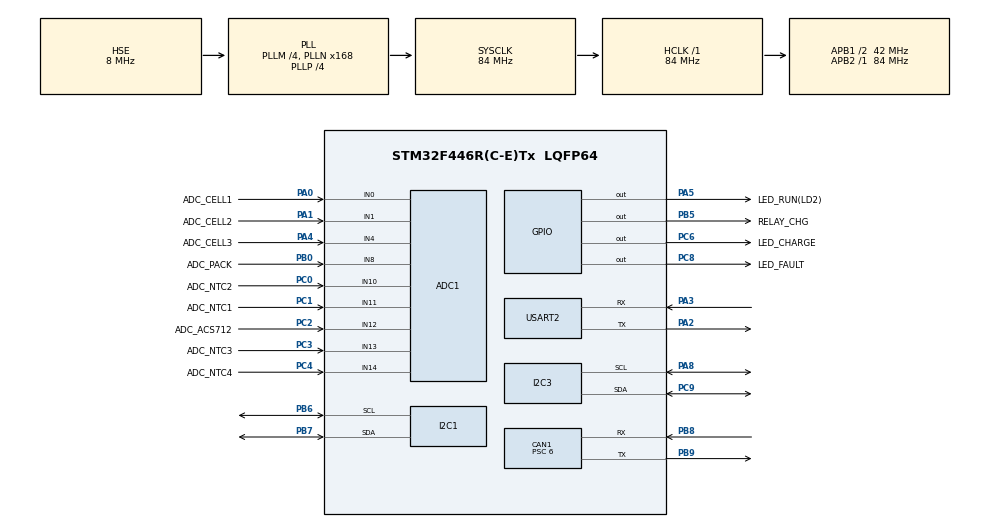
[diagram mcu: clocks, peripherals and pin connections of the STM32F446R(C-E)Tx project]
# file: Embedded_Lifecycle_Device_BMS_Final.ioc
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ADC1.Channel-0\#ChannelRegularConversion=ADC_CHANNEL_0
ADC1.Channel-1\#ChannelRegularConversion=ADC_CHANNEL_1
ADC1.Channel-2\#ChannelRegularConversion=ADC_CHANNEL_4
ADC1.Channel-3\#ChannelRegularConversion=ADC_CHANNEL_8
ADC1.Channel-4\#ChannelRegularConversion=ADC_CHANNEL_11
ADC1.Channel-5\#ChannelRegularConversion=ADC_CHANNEL_10
ADC1.Channel-6\#ChannelRegularConversion=ADC_CHANNEL_13
ADC1.Channel-7\#ChannelRegularConversion=ADC_CHANNEL_14
ADC1.Channel-8\#ChannelRegularConversion=ADC_CHANNEL_12
ADC1.Channel-9\#ChannelRegularConversion=ADC_CHANNEL_VREFINT
ADC1.ClockPrescaler=ADC_CLOCK_SYNC_PCLK_DIV8
ADC1.ContinuousConvMode=ENABLE
ADC1.DMAContinuousRequests=ENABLE
ADC1.NbrOfConversion=10
ADC1.NbrOfConversionFlag=1
ADC1.Rank-0\#ChannelRegularConversion=1
ADC1.Rank-1\#ChannelRegularConversion=2
ADC1.Rank-2\#ChannelRegularConversion=3
ADC1.Rank-3\#ChannelRegularConversion=4
ADC1.Rank-4\#ChannelRegularConversion=5
ADC1.Rank-5\#ChannelRegularConversion=6
ADC1.Rank-6\#ChannelRegularConversion=7
ADC1.Rank-7\#ChannelRegularConversion=8
ADC1.Rank-8\#ChannelRegularConversion=9
ADC1.Rank-9\#ChannelRegularConversion=10
ADC1.SamplingTime-0\#ChannelRegularConversion=ADC_SAMPLETIME_480CYCLES
ADC1.SamplingTime-1\#ChannelRegularConversion=ADC_SAMPLETIME_480CYCLES
ADC1.SamplingTime-2\#ChannelRegularConversion=ADC_SAMPLETIME_480CYCLES
ADC1.SamplingTime-3\#ChannelRegularConversion=ADC_SAMPLETIME_480CYCLES
ADC1.SamplingTime-4\#ChannelRegularConversion=ADC_SAMPLETIME_480CYCLES
ADC1.SamplingTime-5\#ChannelRegularConversion=ADC_SAMPLETIME_480CYCLES
ADC1.SamplingTime-6\#ChannelRegularConversion=ADC_SAMPLETIME_480CYCLES
ADC1.SamplingTime-7\#ChannelRegularConversion=ADC_SAMPLETIME_480CYCLES
ADC1.SamplingTime-8\#ChannelRegularConversion=ADC_SAMPLETIME_480CYCLES
ADC1.SamplingTime-9\#ChannelRegularConversion=ADC_SAMPLETIME_480CYCLES
ADC1.ScanConvMode=ENABLE
ADC1.master=1
CAN1.ABOM=ENABLE
CAN1.BS1=CAN_BS1_11TQ
CAN1.BS2=CAN_BS2_2TQ
CAN1.CalculateBaudRate=500000
CAN1.CalculateTimeBit=2000
CAN1.CalculateTimeQuantum=142.85714285714286
CAN1.Mode=CAN_MODE_NORMAL
CAN1.NART=ENABLE
CAN1.Prescaler=6
Dma.ADC1.0.Direction=DMA_PERIPH_TO_MEMORY
Dma.ADC1.0.FIFOMode=DMA_FIFOMODE_DISABLE
Dma.ADC1.0.Instance=DMA2_Stream0
Dma.ADC1.0.MemDataAlignment=DMA_MDATAALIGN_HALFWORD
Dma.ADC1.0.MemInc=DMA_MINC_ENABLE
Dma.ADC1.0.Mode=DMA_CIRCULAR
Dma.ADC1.0.PeriphDataAlignment=DMA_PDATAALIGN_HALFWORD
Dma.ADC1.0.PeriphInc=DMA_PINC_DISABLE
Dma.ADC1.0.Priority=DMA_PRIORITY_LOW
Dma.Request0=ADC1
I2C1.I2C_Mode=I2C_Fast
I2C3.I2C_Mode=I2C_Fast
Mcu.Family=STM32F4
Mcu.Name=STM32F446R(C-E)Tx
Mcu.Package=LQFP64
NVIC.CAN1_RX0_IRQn=true\:0\:0\:false\:false\:true\:true\:true\:true
NVIC.DMA2_Stream0_IRQn=true\:0\:0\:false\:false\:true\:false\:true\:true
NVIC.PriorityGroup=NVIC_PRIORITYGROUP_4
NVIC.USART2_IRQn=true\:0\:0\:false\:false\:true\:true\:true\:true
PA0-WKUP.GPIO_Label=ADC_CELL1
PA0-WKUP.Signal=ADCx_IN0
PA1.GPIO_Label=ADC_CELL2
PA1.Signal=ADCx_IN1
PA2.Mode=Asynchronous
PA2.Signal=USART2_TX
PA3.Mode=Asynchronous
PA3.Signal=USART2_RX
PA4.GPIO_Label=ADC_CELL3
PA4.Signal=ADCx_IN4
PA5.GPIO_Label=LED_RUN(LD2)
PA5.Signal=GPIO_Output
PA8.Mode=I2C
PA8.Signal=I2C3_SCL
PB0.GPIO_Label=ADC_PACK
PB0.Signal=ADCx_IN8
PB5.GPIO_Label=RELAY_CHG
PB5.Signal=GPIO_Output
PB6.Mode=I2C
PB6.Signal=I2C1_SCL
PB7.Mode=I2C
PB7.Signal=I2C1_SDA
PB8.Mode=CAN_Activate
PB8.Signal=CAN1_RX
PB9.Mode=CAN_Activate
PB9.Signal=CAN1_TX
PC0.GPIO_Label=ADC_NTC2
PC0.Signal=ADCx_IN10
PC1.GPIO_Label=ADC_NTC1
PC1.Signal=ADCx_IN11
PC2.GPIO_Label=ADC_ACS712
PC2.Signal=ADCx_IN12
PC3.GPIO_Label=ADC_NTC3
PC3.Signal=ADCx_IN13
PC4.GPIO_Label=ADC_NTC4
PC4.Signal=ADCx_IN14
PC6.GPIO_Label=LED_CHARGE
PC6.Signal=GPIO_Output
PC8.GPIO_Label=LED_FAULT
PC8.Signal=GPIO_Output
PC9.Mode=I2C
PC9.Signal=I2C3_SDA
PH0-OSC_IN.Mode=HSE-External-Clock-Source
PH0-OSC_IN.Signal=RCC_OSC_IN
PH1-OSC_OUT.Mode=HSE-External-Clock-Source
PH1-OSC_OUT.Signal=RCC_OSC_OUT
ProjectManager.HeapSize=0x200
ProjectManager.StackSize=0x400
ProjectManager.TargetToolchain=CMake
RCC.AHBFreq_Value=84000000
RCC.APB1CLKDivider=RCC_HCLK_DIV2
RCC.APB1Freq_Value=42000000
RCC.APB1TimFreq_Value=84000000
RCC.APB2Freq_Value=84000000
RCC.APB2TimFreq_Value=84000000
RCC.CortexFreq_Value=84000000
RCC.HCLKFreq_Value=84000000
RCC.HSE_VALUE=8000000
RCC.PLLM=4
RCC.PLLN=168
RCC.PLLP=RCC_PLLP_DIV4
RCC.PLLSourceVirtual=RCC_PLLSOURCE_HSE
RCC.SYSCLKFreq_VALUE=84000000
RCC.SYSCLKSource=RCC_SYSCLKSOURCE_PLLCLK
RCC.USBFreq_Value=168000000
RCC.VCOOutputFreq_Value=336000000
SH.ADCx_IN0.0=ADC1_IN0,IN0
SH.ADCx_IN1.0=ADC1_IN1,IN1
SH.ADCx_IN10.0=ADC1_IN10,IN10
SH.ADCx_IN11.0=ADC1_IN11,IN11
SH.ADCx_IN12.0=ADC1_IN12,IN12
SH.ADCx_IN13.0=ADC1_IN13,IN13
SH.ADCx_IN14.0=ADC1_IN14,IN14
SH.ADCx_IN4.0=ADC1_IN4,IN4
SH.ADCx_IN8.0=ADC1_IN8,IN8
USART2.VirtualMode=VM_ASYNC
VP_ADC1_Vref_Input.Mode=IN-Vrefint
board=custom

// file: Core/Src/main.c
/* USER CODE BEGIN Header */
/**
  ******************************************************************************
  * @file           : main.c
  * @brief          : Main program body
  ******************************************************************************
  * @attention
  *
  * Copyright (c) 2026 STMicroelectronics.
  * All rights reserved.
  *
  * This software is licensed under terms that can be found in the LICENSE file
  * in the root directory of this software component.
  * If no LICENSE file comes with this software, it is provided AS-IS.
  *
  ******************************************************************************
  */
/* USER CODE END Header */
#include "main.h"
#include "adc.h"
#include "can.h"
#include "dma.h"
#include "i2c.h"
#include "usart.h"
#include "gpio.h"

/* USER CODE BEGIN Includes */
#include "bms_app.h"
/* USER CODE END Includes */

void SystemClock_Config(void);

int main(void)
{

  /* MCU Configuration--------------------------------------------------------*/

  /* Reset of all peripherals, Initializes the Flash interface and the Systick. */
  HAL_Init();

  /* Configure the system clock */
  SystemClock_Config();

  /* Initialize all configured peripherals */
  MX_GPIO_Init();
  MX_DMA_Init();
  MX_ADC1_Init();
  MX_CAN1_Init();
  MX_USART2_UART_Init();
  MX_I2C1_Init();
  MX_I2C3_Init();
  /* USER CODE BEGIN 2 */
  bms_app_init();
  /* USER CODE END 2 */

  /* Infinite loop */
  while (1)
  {

    /* USER CODE BEGIN 3 */
    bms_app_main();
  }
  /* USER CODE END 3 */
}

void SystemClock_Config(void)
{
  RCC_OscInitTypeDef RCC_OscInitStruct = {0};
  RCC_ClkInitTypeDef RCC_ClkInitStruct = {0};

  /** Configure the main internal regulator output voltage
  */
  __HAL_RCC_PWR_CLK_ENABLE();
  __HAL_PWR_VOLTAGESCALING_CONFIG(PWR_REGULATOR_VOLTAGE_SCALE3);

  /** Initializes the RCC Oscillators according to the specified parameters
  * in the RCC_OscInitTypeDef structure.
  */
  RCC_OscInitStruct.OscillatorType = RCC_OSCILLATORTYPE_HSE;
  RCC_OscInitStruct.HSEState = RCC_HSE_BYPASS;
  RCC_OscInitStruct.PLL.PLLState = RCC_PLL_ON;
  RCC_OscInitStruct.PLL.PLLSource = RCC_PLLSOURCE_HSE;
  RCC_OscInitStruct.PLL.PLLM = 4;
  RCC_OscInitStruct.PLL.PLLN = 168;
  RCC_OscInitStruct.PLL.PLLP = RCC_PLLP_DIV4;
  RCC_OscInitStruct.PLL.PLLQ = 2;
  RCC_OscInitStruct.PLL.PLLR = 2;
  if (HAL_RCC_OscConfig(&RCC_OscInitStruct) != HAL_OK)
  {
    Error_Handler();
  }

  /** Initializes the CPU, AHB and APB buses clocks
  */
  RCC_ClkInitStruct.ClockType = RCC_CLOCKTYPE_HCLK|RCC_CLOCKTYPE_SYSCLK
                              |RCC_CLOCKTYPE_PCLK1|RCC_CLOCKTYPE_PCLK2;
  RCC_ClkInitStruct.SYSCLKSource = RCC_SYSCLKSOURCE_PLLCLK;
  RCC_ClkInitStruct.AHBCLKDivider = RCC_SYSCLK_DIV1;
  RCC_ClkInitStruct.APB1CLKDivider = RCC_HCLK_DIV2;
  RCC_ClkInitStruct.APB2CLKDivider = RCC_HCLK_DIV1;

  if (HAL_RCC_ClockConfig(&RCC_ClkInitStruct, FLASH_LATENCY_2) != HAL_OK)
  {
    Error_Handler();
  }
}

void Error_Handler(void)
{
  __disable_irq();
  while (1)
  {
  }
}
